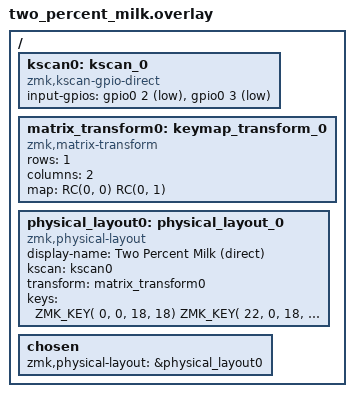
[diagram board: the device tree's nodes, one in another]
// SPDX-License-Identifier: MIT
// Two Percent Milk — direct-pin + ZMK Studio physical layout
// Works out-of-the-box for nice_nano_v2 with two switches on P0.02 and P0.03.

#include <zephyr/dt-bindings/gpio/gpio.h>
#include <dt-bindings/zmk/matrix_transform.h>

/ {
    /* ---------- DIRECT-PIN KSCAN --------------------------------------- */
    kscan0: kscan_0 {
        compatible = "zmk,kscan-gpio-direct";

        /* One entry per key, in the logical order you want.
         * Example below: two keys on P0.02 and P0.03, active-low to GND.
         * If you change pins, update 'columns', 'map', and 'keys' too.
         */
        input-gpios = <
            &gpio0  2 (GPIO_ACTIVE_LOW | GPIO_PULL_UP)   /* Key 0 */
            &gpio0  3 (GPIO_ACTIVE_LOW | GPIO_PULL_UP)   /* Key 1 */
        >;
    };

    /* ---------- 1×N TRANSFORM (N = number of input-gpios) -------------- */
    matrix_transform0: keymap_transform_0 {
        compatible = "zmk,matrix-transform";
        rows = <1>;
        columns = <2>;                          /* <-- set to your key count */

        /* Direct-pin: pin index k == column k → RC(0, k) */
        map = <
            RC(0, 0) RC(0, 1)
        >;
    };

    /* ---------- PHYSICAL LAYOUT (used by Studio) ----------------------- */
    physical_layout0: physical_layout_0 {
        compatible = "zmk,physical-layout";
        display-name = "Two Percent Milk (direct)";

        /* Wire kscan + transform (REQUIRED) */
        kscan = <&kscan0>;
        transform = <&matrix_transform0>;

        /* Optional but recommended: rectangles for Studio UI (mm).
         * Tweak x,y,w,h to match your board. Below places two 18×18 “keys”
         * with 4 mm gap, centered near origin.
         *
         * ZMK_KEY(x_mm, y_mm, w_mm, h_mm)
         */
        keys = <
            ZMK_KEY(  0,  0, 18, 18)   /* Key 0 (maps to RC(0,0)) */
            ZMK_KEY( 22,  0, 18, 18)   /* Key 1 (maps to RC(0,1)) */
        >;
    };

    /* ---------- SELECT LAYOUT FOR STUDIO ------------------------------- */
    chosen {
        zmk,physical-layout = &physical_layout0;   /* Do NOT set zmk,matrix-transform here */
    };
};
